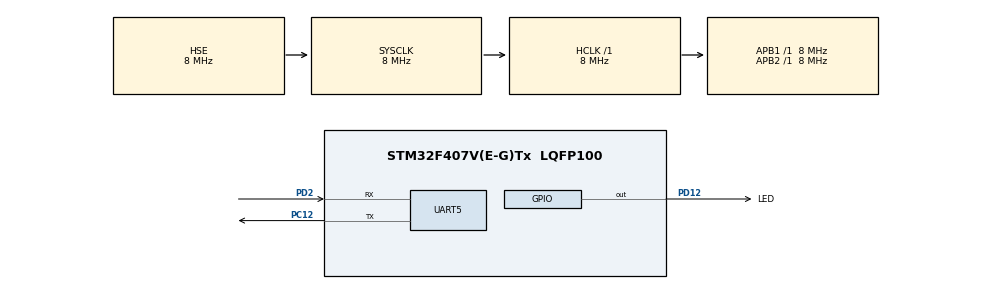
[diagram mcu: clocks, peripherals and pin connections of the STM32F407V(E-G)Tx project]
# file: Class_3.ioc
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Mcu.Family=STM32F4
Mcu.Name=STM32F407V(E-G)Tx
Mcu.Package=LQFP100
NVIC.PriorityGroup=NVIC_PRIORITYGROUP_4
PA13.Mode=Serial_Wire
PA13.Signal=SYS_JTMS-SWDIO
PA14.Mode=Serial_Wire
PA14.Signal=SYS_JTCK-SWCLK
PC12.Mode=Asynchronous
PC12.Signal=UART5_TX
PD12.GPIO_Label=LED
PD12.Signal=GPIO_Output
PD2.Mode=Asynchronous
PD2.Signal=UART5_RX
PH0-OSC_IN.Mode=HSE-External-Oscillator
PH0-OSC_IN.Signal=RCC_OSC_IN
PH1-OSC_OUT.Mode=HSE-External-Oscillator
PH1-OSC_OUT.Signal=RCC_OSC_OUT
ProjectManager.HeapSize=0x200
ProjectManager.StackSize=0x400
ProjectManager.TargetToolchain=STM32CubeIDE
RCC.48MHZClocksFreq_Value=24000000
RCC.AHBFreq_Value=8000000
RCC.APB1Freq_Value=8000000
RCC.APB1TimFreq_Value=8000000
RCC.APB2Freq_Value=8000000
RCC.APB2TimFreq_Value=8000000
RCC.CortexFreq_Value=8000000
RCC.HCLKFreq_Value=8000000
RCC.HSE_VALUE=8000000
RCC.HSI_VALUE=16000000
RCC.LSE_VALUE=32768
RCC.PLLSourceVirtual=RCC_PLLSOURCE_HSE
RCC.SYSCLKFreq_VALUE=8000000
RCC.SYSCLKSource=RCC_SYSCLKSOURCE_HSE
RCC.VCOOutputFreq_Value=96000000
UART5.VirtualMode=Asynchronous
board=custom

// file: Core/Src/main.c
/* USER CODE BEGIN Header */
/**
  ******************************************************************************
  * @file           : main.c
  * @brief          : Main program body
  ******************************************************************************
  * @attention
  *
  * Copyright (c) 2023 STMicroelectronics.
  * All rights reserved.
  *
  * This software is licensed under terms that can be found in the LICENSE file
  * in the root directory of this software component.
  * If no LICENSE file comes with this software, it is provided AS-IS.
  *
  ******************************************************************************
  */
/* USER CODE END Header */
#include "main.h"

/* USER CODE BEGIN Includes */
#include "string.h"
/* USER CODE END Includes */

UART_HandleTypeDef huart5;

void SystemClock_Config(void);
static void MX_GPIO_Init(void);
static void MX_UART5_Init(void);

/* USER CODE BEGIN 0 */
char veri[20];
char TxBuffer[100000];
int start,difference;

/* USER CODE END 0 */

int main(void)
{

  /* MCU Configuration--------------------------------------------------------*/

  /* Reset of all peripherals, Initializes the Flash interface and the Systick. */
  HAL_Init();

  /* Configure the system clock */
  SystemClock_Config();

  /* Initialize all configured peripherals */
  MX_GPIO_Init();
  MX_UART5_Init();
  /* USER CODE BEGIN 2 */
memset(TxBuffer,'a',100000);

  /* USER CODE END 2 */

  /* Infinite loop */
  while (1)
  {

    /* USER CODE BEGIN 3 */
	  HAL_GPIO_WritePin(LED_GPIO_Port, LED_Pin,GPIO_PIN_SET);
	  start= HAL_GetTick();
	  //strcpy(veri,"LED HİGH\r\n");
	  //HAL_UART_Transmit(&huart5,(uint8_t *)veri , strlen(veri), 1000);
	  HAL_UART_Transmit(&huart5,(uint8_t *)TxBuffer , strlen(TxBuffer),HAL_MAX_DELAY);
	  difference= HAL_GetTick()-start;
	  HAL_Delay(400);
	  HAL_GPIO_WritePin(LED_GPIO_Port, LED_Pin,GPIO_PIN_RESET);
	  strcpy(veri,"LED LOW\r\n");
	 // HAL_UART_Transmit(&huart5,(uint8_t *)veri , strlen(veri), 1000);
	  HAL_Delay(400);
  }
  /* USER CODE END 3 */
}

void SystemClock_Config(void)
{
  RCC_OscInitTypeDef RCC_OscInitStruct = {0};
  RCC_ClkInitTypeDef RCC_ClkInitStruct = {0};

  /** Configure the main internal regulator output voltage
  */
  __HAL_RCC_PWR_CLK_ENABLE();
  __HAL_PWR_VOLTAGESCALING_CONFIG(PWR_REGULATOR_VOLTAGE_SCALE1);
  /** Initializes the RCC Oscillators according to the specified parameters
  * in the RCC_OscInitTypeDef structure.
  */
  RCC_OscInitStruct.OscillatorType = RCC_OSCILLATORTYPE_HSE;
  RCC_OscInitStruct.HSEState = RCC_HSE_ON;
  RCC_OscInitStruct.PLL.PLLState = RCC_PLL_NONE;
  if (HAL_RCC_OscConfig(&RCC_OscInitStruct) != HAL_OK)
  {
    Error_Handler();
  }
  /** Initializes the CPU, AHB and APB buses clocks
  */
  RCC_ClkInitStruct.ClockType = RCC_CLOCKTYPE_HCLK|RCC_CLOCKTYPE_SYSCLK
                              |RCC_CLOCKTYPE_PCLK1|RCC_CLOCKTYPE_PCLK2;
  RCC_ClkInitStruct.SYSCLKSource = RCC_SYSCLKSOURCE_HSE;
  RCC_ClkInitStruct.AHBCLKDivider = RCC_SYSCLK_DIV1;
  RCC_ClkInitStruct.APB1CLKDivider = RCC_HCLK_DIV1;
  RCC_ClkInitStruct.APB2CLKDivider = RCC_HCLK_DIV1;

  if (HAL_RCC_ClockConfig(&RCC_ClkInitStruct, FLASH_LATENCY_0) != HAL_OK)
  {
    Error_Handler();
  }
}

static void MX_UART5_Init(void)
{

  huart5.Instance = UART5;
  huart5.Init.BaudRate = 115200;
  huart5.Init.WordLength = UART_WORDLENGTH_8B;
  huart5.Init.StopBits = UART_STOPBITS_1;
  huart5.Init.Parity = UART_PARITY_NONE;
  huart5.Init.Mode = UART_MODE_TX_RX;
  huart5.Init.HwFlowCtl = UART_HWCONTROL_NONE;
  huart5.Init.OverSampling = UART_OVERSAMPLING_16;
  if (HAL_UART_Init(&huart5) != HAL_OK)
  {
    Error_Handler();
  }

}

static void MX_GPIO_Init(void)
{
  GPIO_InitTypeDef GPIO_InitStruct = {0};

  /* GPIO Ports Clock Enable */
  __HAL_RCC_GPIOH_CLK_ENABLE();
  __HAL_RCC_GPIOD_CLK_ENABLE();
  __HAL_RCC_GPIOA_CLK_ENABLE();
  __HAL_RCC_GPIOC_CLK_ENABLE();

  /*Configure GPIO pin Output Level */
  HAL_GPIO_WritePin(LED_GPIO_Port, LED_Pin, GPIO_PIN_RESET);

  /*Configure GPIO pin : LED_Pin */
  GPIO_InitStruct.Pin = LED_Pin;
  GPIO_InitStruct.Mode = GPIO_MODE_OUTPUT_PP;
  GPIO_InitStruct.Pull = GPIO_NOPULL;
  GPIO_InitStruct.Speed = GPIO_SPEED_FREQ_LOW;
  HAL_GPIO_Init(LED_GPIO_Port, &GPIO_InitStruct);

}

void Error_Handler(void)
{
  __disable_irq();
  while (1)
  {
  }
}
